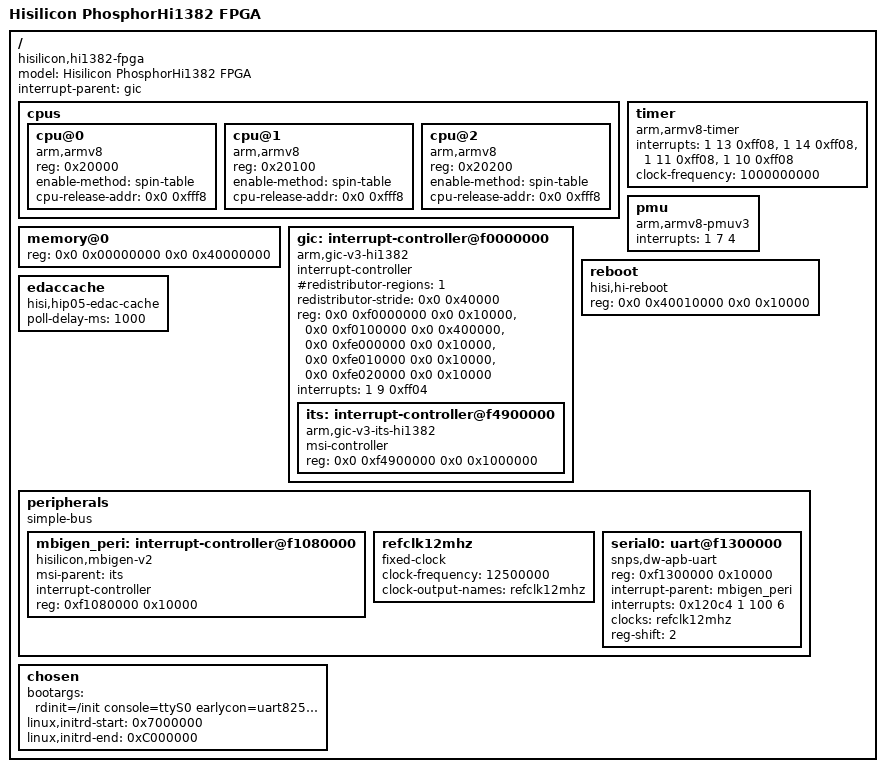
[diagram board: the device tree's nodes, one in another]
/**
 * dts file for Hisilicon PhosphorHi1382 FPGA B500
 *
 * Copyright (C) 2015, Hisilicon Ltd.
 *
 * This program is free software; you can redistribute it and/or modify
 * it under the terms of the GNU General Public License version 2 as
 * publishhed by the Free Software Foundation.
 *
 */

/dts-v1/;

/memreserve/ 0x00000000 0x00010000;

/ {
	#address-cells = <2>;
	#size-cells = <2>;
	model = "Hisilicon PhosphorHi1382 FPGA";
	compatible = "hisilicon,hi1382-fpga", "hisilicon,hisi-Hi1382";
	interrupt-parent = <&gic>;

	cpus {
		#address-cells = <1>;
		#size-cells = <0>;

		cpu@0 {
			device_type = "cpu";
			compatible = "arm,armv8";
			reg = <0x20000>;
			enable-method = "spin-table";
			cpu-release-addr = <0x0 0xfff8>;
		};

		cpu@1 {
			device_type = "cpu";
			compatible = "arm,armv8";
			reg = <0x20100>;
			enable-method = "spin-table";
			cpu-release-addr = <0x0 0xfff8>;
		};

		cpu@2 {
			device_type = "cpu";
			compatible = "arm,armv8";
			reg = <0x20200>;
			enable-method = "spin-table";
			cpu-release-addr = <0x0 0xfff8>;
		};
	};

	memory@0 {
		device_type = "memory";
		reg = <0x0 0x00000000 0x0 0x40000000>;
	};

	gic: interrupt-controller@f0000000 {
		compatible = "arm,gic-v3-hi1382";
		#interrupt-cells = <3>;
		#address-cells = <2>;
		#size-cells = <2>;
		ranges;
		interrupt-controller;
		#redistributor-regions = <1>;
		redistributor-stride = <0x0 0x40000>;
		reg = <0x0 0xf0000000 0x0 0x10000>,	/* GICD */
		      <0x0 0xf0100000 0x0 0x400000>,	/* GICR */
		      <0x0 0xfe000000 0x0 0x10000>,	/* GICC */
		      <0x0 0xfe010000 0x0 0x10000>,     /* GICH */
		      <0x0 0xfe020000 0x0 0x10000>;     /* GICV */
		interrupts = <1 9 0xff04>;

		its: interrupt-controller@f4900000 {
			compatible = "arm,gic-v3-its-hi1382";
			msi-controller;
			reg = <0x0 0xf4900000 0x0 0x1000000>;
		};
	};

	timer {
		compatible = "arm,armv8-timer";
		interrupts = <1 13 0xff08>,
			     <1 14 0xff08>,
			     <1 11 0xff08>,
			     <1 10 0xff08>;
		clock-frequency = <1000000000>;
	};

	pmu {
		compatible = "arm,armv8-pmuv3";
		interrupts = <1 7 4>;
	};

	reboot {
		compatible = "hisi,hi-reboot";
		reg = <0x0 0x40010000 0x0 0x10000>;
	};

	edaccache {
		compatible = "hisi,hip05-edac-cache";
		poll-delay-ms = <1000>;
	};

	peripherals {
		compatible = "simple-bus";
		#address-cells = <1>;
		#size-cells = <1>;
		ranges = <0x0 0x00000000 0x0 0xffffffff>;

		mbigen_peri: interrupt-controller@f1080000 {
			compatible = "hisilicon,mbigen-v2";
			msi-parent = <&its>;
			interrupt-controller;
			#interrupt-cells = <4>;
			reg = <0xf1080000 0x10000>;
		};

		refclk12mhz: refclk12mhz {
			compatible = "fixed-clock";
			#clock-cells = <0>;
			clock-frequency = <12500000>;
			clock-output-names = "refclk12mhz";
		};

		serial0: uart@f1300000 {
			compatible = "snps,dw-apb-uart";
			#address-cells = <1>;
			#size-cells = <0>;
			reg = <0xf1300000 0x10000>;
			interrupt-parent = <&mbigen_peri>;
			interrupts = <0x120c4 1 100 6>;
			clocks = <&refclk12mhz>;
			clock-names = "apb_pclk";
			reg-shift = <2>;
		};

	};

	chosen {
		bootargs = "rdinit=/init console=ttyS0 earlycon=uart8250,mmio32,0xf1300000";
		linux,initrd-start = <0x7000000>;
		linux,initrd-end = <0xC000000>;
	};
};

